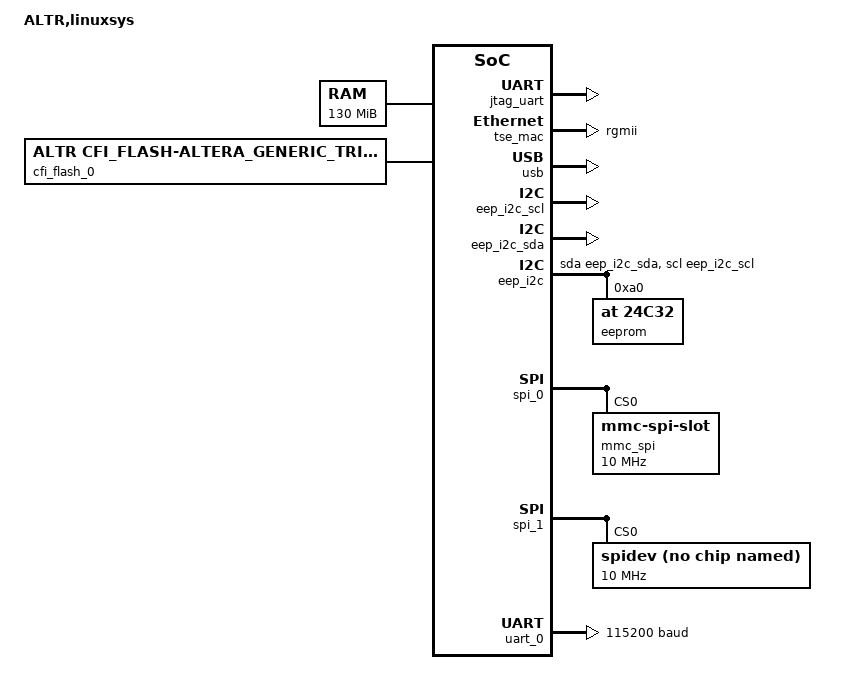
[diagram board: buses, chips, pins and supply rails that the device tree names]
/*
 * This devicetree is generated by sopc2dts
 * Sopc2dts is written by Walter Goossens <waltergoossens@home.nl>
 * in cooperation with the nios2 community <Nios2-dev@sopc.et.ntust.edu.tw>
 */
/dts-v1/;

/ {
	model = "ALTR,linuxsys";
	compatible = "ALTR,linuxsys";
	#address-cells = < 1 >;
	#size-cells = < 1 >;

	cpus {
		#address-cells = < 1 >;
		#size-cells = < 0 >;

		cpu: cpu@0x0 {
			device_type = "cpu";
			compatible = "ALTR,nios2-11.1";
			reg = < 0x00000000 >;
			interrupt-controller;
			#interrupt-cells = < 1 >;
			clock-frequency = < 100000000 >;	/* embeddedsw.CMacro.CPU_FREQ type NUMBER */
			dcache-line-size = < 32 >;	/* embeddedsw.CMacro.DCACHE_LINE_SIZE type NUMBER */
			icache-line-size = < 32 >;	/* embeddedsw.CMacro.ICACHE_LINE_SIZE type NUMBER */
			dcache-size = < 4096 >;	/* embeddedsw.CMacro.DCACHE_SIZE type NUMBER */
			icache-size = < 8192 >;	/* embeddedsw.CMacro.ICACHE_SIZE type NUMBER */
			ALTR,implementation = "fast";	/* embeddedsw.CMacro.CPU_IMPLEMENTATION type STRING*/
			ALTR,pid-num-bits = < 10 >;	/* embeddedsw.CMacro.PROCESS_ID_NUM_BITS type NUMBER */
			ALTR,tlb-num-ways = < 16 >;	/* embeddedsw.CMacro.TLB_NUM_WAYS type NUMBER */
			ALTR,tlb-num-entries = < 256 >;	/* embeddedsw.CMacro.TLB_NUM_ENTRIES type NUMBER */
			ALTR,tlb-ptr-sz = < 8 >;	/* embeddedsw.CMacro.TLB_PTR_SZ type NUMBER */
			ALTR,has-div;	/* embeddedsw.CMacro.HARDWARE_DIVIDE_PRESENT type NUMBER*/
			ALTR,has-mul;	/* embeddedsw.CMacro.HARDWARE_MULTIPLY_PRESENT type NUMBER*/
			ALTR,reset-addr = < 0xc0000000 >;	/* embeddedsw.CMacro.RESET_ADDR type NUMBER */
			ALTR,fast-tlb-miss-addr = < 0xc9000000 >;	/* embeddedsw.CMacro.FAST_TLB_MISS_EXCEPTION_ADDR type NUMBER */
			ALTR,exception-addr = < 0xc0000020 >;	/* embeddedsw.CMacro.EXCEPTION_ADDR type NUMBER */
		}; //end cpu@0x0 (cpu)
	}; //end cpus

	memory@0 {
		device_type = "memory";
		reg = < 0x00000000 0x08000000
			0x09000000 0x00000200
			0x0C000000 0x00200000 >;
	}; //end memory@0

	sopc@0 {
		ranges;
		#address-cells = < 1 >;
		#size-cells = < 1 >;
		device_type = "soc";
		compatible = "ALTR,avalon", "simple-bus";
		bus-frequency = < 100000000 >;

		jtag_uart: serial@0x80034b0 {
			compatible = "ALTR,juart-11.1", "ALTR,juart-1.0";
			reg = < 0x080034B0 0x00000008 >;
			interrupt-parent = < &cpu >;
			interrupts = < 2 >;
		}; //end serial@0x80034b0 (jtag_uart)

		timer: timer@0x8003480 {
			compatible = "ALTR,timer-11.1", "ALTR,timer-1.0";
			reg = < 0x08003480 0x00000020 >;
			interrupt-parent = < &cpu >;
			interrupts = < 1 >;
			clock-frequency = < 100000000 >;
		}; //end timer@0x8003480 (timer)

		altpll_0: clock@0x80034a0 {
			compatible = "ALTR,pll-11.1", "ALTR,pll-1.0";
			reg = < 0x080034A0 0x00000010 >;
		}; //end clock@0x80034a0 (altpll_0)

		tse_mac: ethernet@0x8003400 {
			compatible = "ALTR,tse-11.1", "ALTR,tse-1.0";
			reg = < 0x08003000 0x00000400
				0x08003440 0x00000040
				0x08003400 0x00000040
				0x08001000 0x00001000 >;
			interrupt-parent = < &cpu >;
			interrupts = < 4 3 >;
			ALTR,rx-fifo-depth = < 2048 >;	/* embeddedsw.CMacro.RECEIVE_FIFO_DEPTH type NUMBER */
			ALTR,tx-fifo-depth = < 2048 >;	/* embeddedsw.CMacro.TRANSMIT_FIFO_DEPTH type NUMBER */
			address-bits = < 48 >;
			max-frame-size = < 1518 >;
			local-mac-address = [ 00 AA BB CC DD EE ];
			phy-mode = "rgmii";
			ALTR,mii-id = < 0 >;
		}; //end ethernet@0x8003400 (tse_mac)

		usb: isp1362@0x82224d8 {
			compatible = "nxp,usb-isp1362-1.0", "nxp,usb-isp1362";
			reg = < 0x082224D8 0x00000008
				0x082224E0 0x00000008 >;
			interrupt-parent = < &cpu >;
			interrupts = < 5 6 >;
		}; //end isp1362@0x82224d8 (usb)

		/*
		ISP1362_IF_0: isp1362@0x8221000 {
			compatible = "nxp,usb-isp1362-1.0", "nxp,usb-isp1362";
			reg = < 0x08221000 0x00000008
				0x08221008 0x00000008 >;
			interrupt-parent = < &cpu >;
			interrupts = < 9 10 >;
		}; //end isp1362@0x8221000 (ISP1362_IF_0)
		*/

		cfi_flash_0: flash@0xa000000 {
			compatible = "ALTR,cfi_flash-altera_generic_tristate_controller", "cfi-flash";
			reg = < 0x0A000000 0x00800000 >;
			bank-width = < 2 >;
			device-width = < 1 >;
			#address-cells = < 1 >;
			#size-cells = < 1 >;

			// MTD partitions (256k, 64k, 1728k, 5632k, 512k)
			u-boot@0 {
				reg = < 0x00000000 0x00040000 >;
			}; //end u-boot@0

			u-boot_cfg@40000 {
				reg = < 0x00040000 0x00010000 >;
			}; //end u-boot_cfg@40000

			kernel@50000 {
				reg = < 0x00050000 0x001C0000 >;
			}; //end linux@50000

			rootfs@200000 {
				reg = < 0x00200000 0x00580000 >;
			}; //end rootfs@200000

			config@780000 {
				reg = < 0x00780000 0x00080000 >;
			}; //end config@780000
		}; //end flash@0xa000000 (cfi_flash_0)

		mm_clock_crossing_bridge_0: bridge@0xb000000 {
			compatible = "ALTR,avalon-11.1", "simple-bus";
			reg = < 0x0B000000 0x00000400 >;
			#address-cells = < 1 >;
			#size-cells = < 1 >;
			ranges = < 0x00000010 0x0B000010 0x00000010
				0x00000100 0x0B000100 0x00000010
				0x00000110 0x0B000110 0x00000010
				0x00000120 0x0B000120 0x00000010
				0x00000130 0x0B000130 0x00000010
				0x000000C0 0x0B0000C0 0x00000010
				0x000000D0 0x0B0000D0 0x00000010
				0x000000E0 0x0B0000E0 0x00000010 >;

			lcd_0: de2lcd@0x10 {
				compatible = "de2lcd,de2lcd-1.0";
				reg = < 0x00000010 0x00000010 >;
			}; //end de2lcd@0x10 (lcd_0)

			sd_clk: gpio@0x100 {
				compatible = "ALTR,pio-11.1", "ALTR,pio-1.0";
				reg = < 0x00000100 0x00000010 >;
				width = < 1 >;	/* width type NUMBER */
				resetvalue = < 0 >;	/* resetValue type NUMBER */
			}; //end gpio@0x100 (sd_clk)

			sd_cmd: gpio@0x110 {
				compatible = "ALTR,pio-11.1", "ALTR,pio-1.0";
				reg = < 0x00000110 0x00000010 >;
				width = < 1 >;	/* width type NUMBER */
				resetvalue = < 0 >;	/* resetValue type NUMBER */
			}; //end gpio@0x110 (sd_cmd)

			sd_dat: gpio@0x120 {
				compatible = "ALTR,pio-11.1", "ALTR,pio-1.0";
				reg = < 0x00000120 0x00000010 >;
				width = < 4 >;	/* width type NUMBER */
				resetvalue = < 0 >;	/* resetValue type NUMBER */
			}; //end gpio@0x120 (sd_dat)

			sd_wp_n: gpio@0x130 {
				compatible = "ALTR,pio-11.1", "ALTR,pio-1.0";
				reg = < 0x00000130 0x00000010 >;
				width = < 1 >;	/* width type NUMBER */
				resetvalue = < 0 >;	/* resetValue type NUMBER */
			}; //end gpio@0x130 (sd_wp_n)

			eep_i2c_scl: gpio@0xc0 {
				compatible = "ALTR,pio-11.1", "ALTR,pio-1.0";
				reg = < 0x000000C0 0x00000010 >;
				width = < 1 >;	/* width type NUMBER */
				resetvalue = < 0 >;	/* resetValue type NUMBER */
				#gpio-cells = <1>;
			}; //end gpio@0xc0 (eep_i2c_scl)

			eep_i2c_sda: gpio@0xd0 {
				compatible = "ALTR,pio-11.1", "ALTR,pio-1.0";
				reg = < 0x000000D0 0x00000010 >;
				width = < 1 >;	/* width type NUMBER */
				resetvalue = < 0 >;	/* resetValue type NUMBER */
				#gpio-cells = <1>;
			}; //end gpio@0xd0 (eep_i2c_sda)

			eep_i2c {
				compatible = "i2c-gpio";
				gpios = < &eep_i2c_sda
					  &eep_i2c_scl >;
				scl-is-output-only;
//				speed-hz = < 2500000 >;
				#address-cells = < 1 >;
				#size-cells = < 0 >;

				eeprom@a0 {
					compatible = "at,24c32";
					reg = < 0xa0 >;
				};
			};

			func_sel: gpio@0xe0 {
				compatible = "ALTR,pio-11.1", "ALTR,pio-1.0";
				reg = < 0x000000E0 0x00000010 >;
				width = < 4 >;	/* width type NUMBER */
				resetvalue = < 0 >;	/* resetValue type NUMBER */
			}; //end gpio@0xe0 (func_sel)

		}; //end bridge@0xb000000 (mm_clock_crossing_bridge_0)

		sysid_qsys_0: sysid@0xba00000 {
			compatible = "ALTR,sysid-11.1", "ALTR,sysid-1.0";
			reg = < 0x0BA00000 0x00000008 >;
		}; //end sysid@0xba00000 (sysid_qsys_0)

		spi_0: spi@0xba10000 {
			compatible = "ALTR,spi-11.1", "ALTR,spi-1.0";
			reg = < 0x0BA10000 0x00000020 >;
			interrupt-parent = < &cpu >;
			interrupts = < 0 >;
			#address-cells = < 1 >;
			#size-cells = < 0 >;

			mmc_spi@0 {
				compatible = "mmc-spi-slot";
				spi-max-frequency = < 10000000 >;
				reg = < 0x00000000 >;
				voltage-ranges = < 3300 3300 >;
			}; //end mmc_spi@0
		}; //end spi@0xba10000 (spi_0)

		spi_1: spi@0xba20000 {
			compatible = "ALTR,spi-11.1", "ALTR,spi-1.0";
			reg = < 0x0BA20000 0x00000020 >;
			interrupt-parent = < &cpu >;
			interrupts = < 8 >;
			#address-cells = < 1 >;
			#size-cells = < 0 >;

			spidev@0 {
				compatible = "spidev";
                                spi-max-frequency = < 10000000 >;
                                reg = < 0x00000000 >;
			}; //end spidev@0
		}; //end spi@0xba20000 (spi_1)

		uart_0: serial@0xd100000 {
			compatible = "ALTR,uart-11.1", "ALTR,uart-1.0";
			reg = < 0x0D100000 0x00000020 >;
			interrupt-parent = < &cpu >;
			interrupts = < 11 >;
			current-speed = < 115200 >;	/* embeddedsw.CMacro.BAUD type NUMBER */
			clock-frequency = < 100000000 >;	/* embeddedsw.CMacro.FREQ type NUMBER */
		}; //end serial@0xd100000 (uart_0)

		test_runner_0: trunner@0xd000000 {
			compatible = "trunner,trunner-1.0";
			reg = < 0x0D000000 0x00000100 >;
			interrupt-parent = < &cpu >;
			interrupts = < 7 >;
		}; //end trunner@0xd000000 (test_runner_0)

		freq_counter_0: fcounter@0xd200000 {
			compatible = "fcounter,fcounter-1.0";
			reg = < 0x0D200000 0x00000400 >;
			interrupt-parent = < &cpu >;
			interrupts = < 12 >;
		}; //end trunner@0xd200000 (freq_counter_0)

		sram_bridge: sram_bridge@0xc000000 {
			compatible = "sram-bridge";
			reg = < 0x0C000000 0x00200000 >;
		}; //end sram_bridge@0xc000000 (sram_bridge)
	}; //end sopc@0

	chosen {
		bootargs = "debug console=ttyAL0,115200";
	}; //end chosen
}; //end /
